# STM32U595 register map
File version: 1.0
CPU: CM33 r0p1, little endian, MPU, FPU, 4 interrupt priority bits
Registers are 32-bit, read-write, reset 0x0 unless marked. A register's access mark holds for its fields unless they carry their own. Offsets are from the block's base; [hi:lo] are bit positions; {n}, {i} and the like mark numbered series; 'fields as' and 'values as' point back to an identical list.

## SYSCFG — System configuration controller
Base 0x46000400
Same registers: SEC_SYSCFG 0x56000400
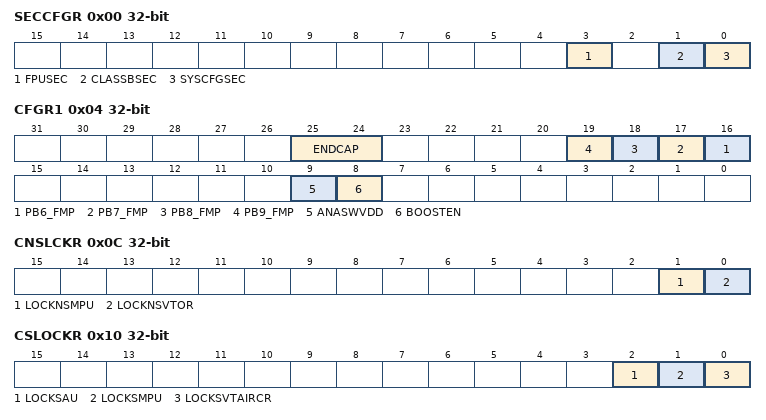
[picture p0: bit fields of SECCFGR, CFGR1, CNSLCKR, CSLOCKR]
0x00 SECCFGR — SYSCFG secure configuration register
  [3] FPUSEC
  [1] CLASSBSEC
  [0] SYSCFGSEC — SYSCFG clock control security
0x04 CFGR1 — configuration register 1
  [25:24] ENDCAP
  [n+10] PB{n}_FMP (n=6..9)
  [9] ANASWVDD — GPIO analog switch control voltage selection
  [8] BOOSTEN — I/O analog switch voltage booster enable
0x08 FPUIMR reset 0x1F — FPU interrupt mask register
  [5:0] FPU_IE — Floating point unit interrupts enable bits
0x0C CNSLCKR — SYSCFG CPU non-secure lock register
  [1] LOCKNSMPU — Non-secure MPU registers lock
  [0] LOCKNSVTOR — VTOR_NS register lock
0x10 CSLOCKR — SYSCFG CPU secure lock register
  [2] LOCKSAU, [1] LOCKSMPU, [0] LOCKSVTAIRCR
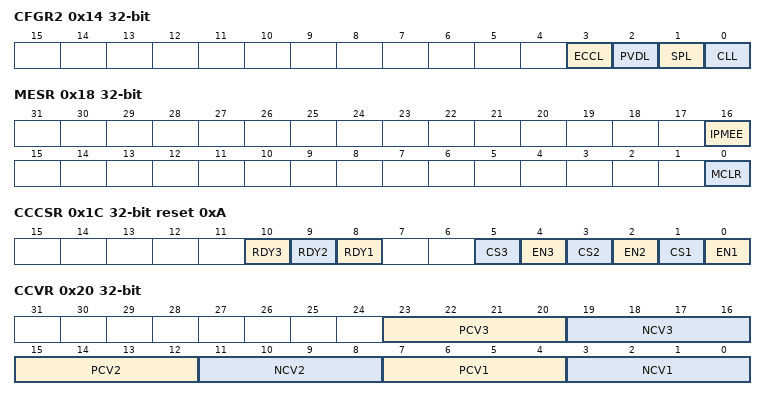
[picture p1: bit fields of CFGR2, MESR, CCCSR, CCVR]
0x14 CFGR2 — configuration register 2
  [3] ECCL — ECC Lock
  [2] PVDL — PVD lock enable bit
  [1] SPL — SRAM ECC lock bit
  [0] CLL — LOCKUP (hardfault) output enable bit
0x18 MESR — memory erase status register
  [16] IPMEE, [0] MCLR
0x1C CCCSR access per field reset 0xA — compensation cell control/status register
  [10] RDY3 ro, [9] RDY2 ro, [8] RDY1 ro, [5] CS3 rw, [4] EN3 rw, [3] CS2 rw, [2] EN2 rw, [1] CS1 rw, [0] EN1 rw
0x20 CCVR ro — compensation cell value register
  [23:20] PCV3, [19:16] NCV3, [15:12] PCV2, [11:8] NCV2, [7:4] PCV1, [3:0] NCV1
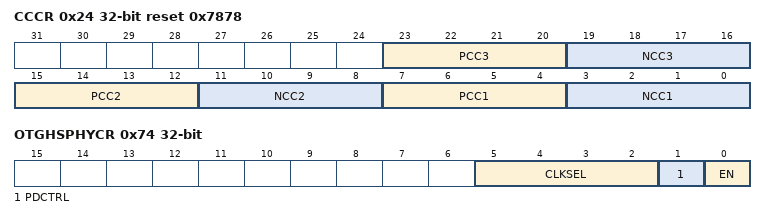
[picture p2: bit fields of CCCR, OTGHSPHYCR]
0x24 CCCR reset 0x7878 — compensation cell code register
  [23:20] PCC3, [19:16] NCC3, [15:12] PCC2, [11:8] NCC2, [7:4] PCC1, [3:0] NCC1
0x2C RSSCMDR — RSS command register
  [15:0] RSSCMD — RSS commands
0x74 OTGHSPHYCR — SYSCFG USB OTG_HS PHY register
  [5:2] CLKSEL, [1] PDCTRL, [0] EN

## TAMP — Tamper and backup registers
Base 0x46007C00
Same registers: SEC_TAMP 0x56007C00
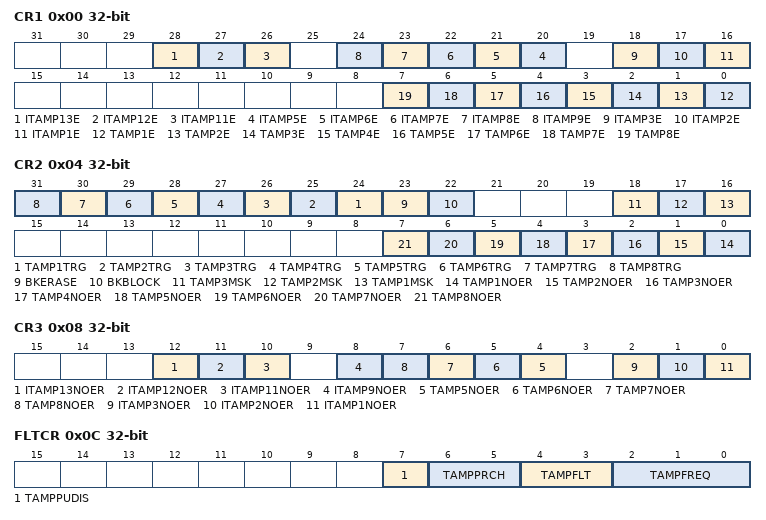
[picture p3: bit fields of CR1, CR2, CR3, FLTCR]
0x00 CR1 — control register 1
  [28] ITAMP13E
  [27] ITAMP12E
  [26] ITAMP11E — TAMP1E
  [n+15] ITAMP{n}E (n=5..9)
  [18] ITAMP3E
  [17] ITAMP2E
  [16] ITAMP1E
  [n-1] TAMP{n}E (n=1..8)
0x04 CR2 — control register 2
  [n+23] TAMP{n}TRG (n=1..8), [23] BKERASE, [22] BKBLOCK, [18] TAMP3MSK, [17] TAMP2MSK, [16] TAMP1MSK, [n-1] TAMP{n}NOER (n=1..8)
0x08 CR3 — control register 3
  [12] ITAMP13NOER, [11] ITAMP12NOER, [10] ITAMP11NOER, [8] ITAMP9NOER, [n-1] TAMP{n}NOER (n=5..8), [2] ITAMP3NOER, [1] ITAMP2NOER, [0] ITAMP1NOER
0x0C FLTCR — TAMP filter control register
  [7] TAMPPUDIS, [6:5] TAMPPRCH, [4:3] TAMPFLT, [2:0] TAMPFREQ
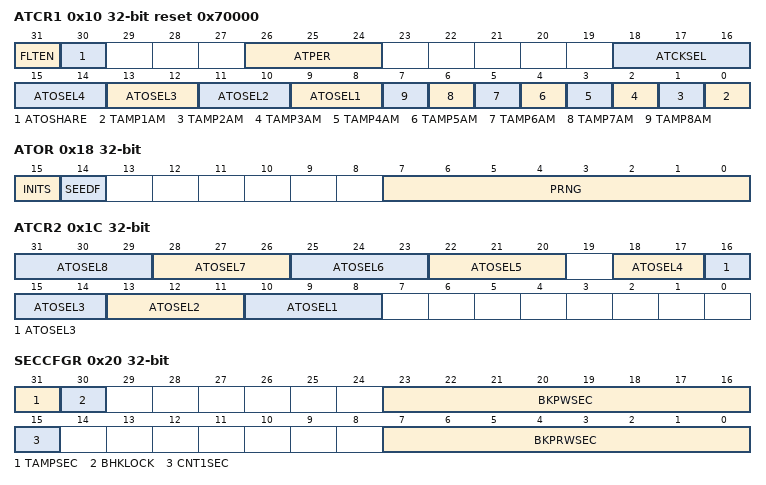
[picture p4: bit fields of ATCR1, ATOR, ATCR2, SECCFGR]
0x10 ATCR1 reset 0x70000 — TAMP active tamper control register
  [31] FLTEN — ATOSHARE
  [30] ATOSHARE
  [26:24] ATPER
  [18:16] ATCKSEL
  [2n+7:2n+6] ATOSEL{n} (n=1..4)
  [n-1] TAMP{n}AM (n=1..8)
0x14 ATSEEDR — TAMP active tamper seed register
  [31:0] SEED
0x18 ATOR ro — TAMP active tamper output register
  [15] INITS, [14] SEEDF, [7:0] PRNG
0x1C ATCR2 — TAMP active tamper control register 2
  [3n+7:3n+5] ATOSEL{n} (n=5..8), [18:17] ATOSEL4, [16:14] ATOSEL3, [13:11] ATOSEL2, [10:8] ATOSEL1
0x20 SECCFGR — TAMP secure mode register
  [31] TAMPSEC, [30] BHKLOCK, [23:16] BKPWSEC, [15] CNT1SEC, [7:0] BKPRWSEC
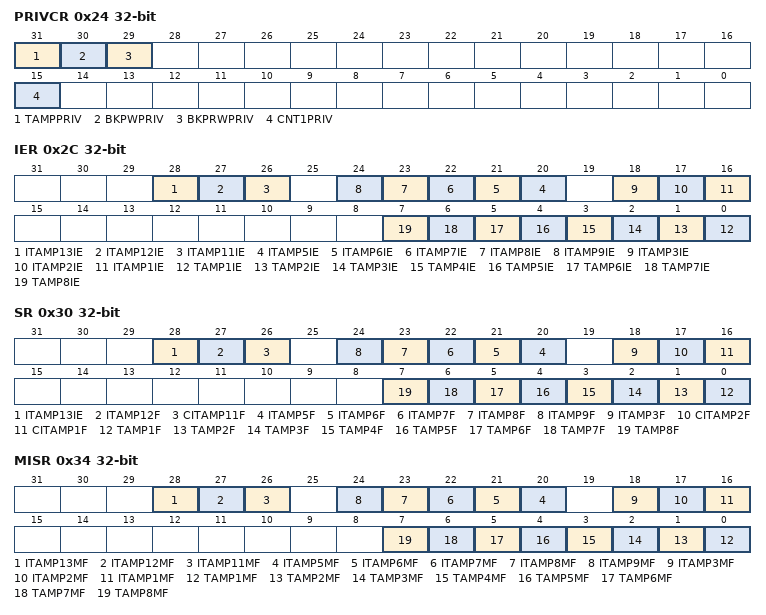
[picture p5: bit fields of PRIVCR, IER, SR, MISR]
0x24 PRIVCR — TAMP privilege mode control register
  [31] TAMPPRIV, [30] BKPWPRIV, [29] BKPRWPRIV, [15] CNT1PRIV
0x2C IER — TAMP interrupt enable register
  [28] ITAMP13IE, [27] ITAMP12IE, [26] ITAMP11IE, [n+15] ITAMP{n}IE (n=5..9), [18] ITAMP3IE, [17] ITAMP2IE, [16] ITAMP1IE, [n-1] TAMP{n}IE (n=1..8)
0x30 SR ro — TAMP status register
  [28] ITAMP13IE, [27] ITAMP12F, [26] CITAMP11F, [n+15] ITAMP{n}F (n=5..9), [18] ITAMP3F, [17] CITAMP2F, [16] CITAMP1F, [n-1] TAMP{n}F (n=1..8)
0x34 MISR ro — TAMP masked interrupt status register
  [28] ITAMP13MF, [27] ITAMP12MF, [26] ITAMP11MF, [n+15] ITAMP{n}MF (n=5..9), [18] ITAMP3MF, [17] ITAMP2MF, [16] ITAMP1MF, [n-1] TAMP{n}MF (n=1..8)
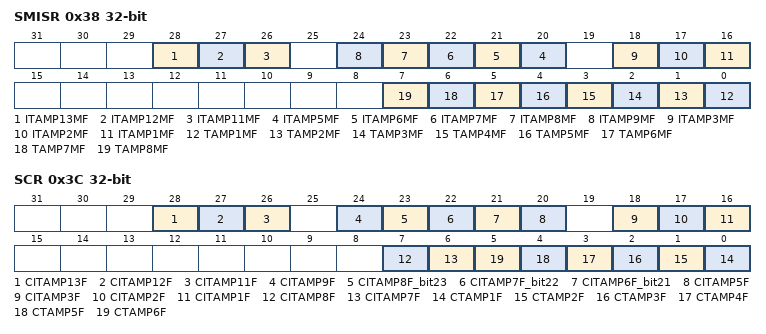
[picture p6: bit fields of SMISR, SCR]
0x38 SMISR ro — TAMP secure masked interrupt status register
  fields as MISR
0x3C SCR — TAMP status clear register
  [28] CITAMP13F
  [27] CITAMP12F
  [26] CITAMP11F
  [24] CITAMP9F
  [23] CITAMP8F_bit23
  [22] CITAMP7F_bit22
  [21] CITAMP6F_bit21
  [20] CITAMP5F
  [18] CITAMP3F
  [17] CITAMP2F
  [16] CITAMP1F
  [7] CITAMP8F — CITAMP3F
  [6] CITAMP7F — CITAMP3F
  [n-1] CTAMP{n}F (n=1..6)
0x40 COUNT1R ro — TAMP monotonic counter 1register
  [31:0] COUNT
0x54 ERCFGR — TAMP erase configuration register
  [0] ERCFG0
{0x100+4i} BKP{i}R (i=0..31) — TAMP backup register
  [31:0] BKP
